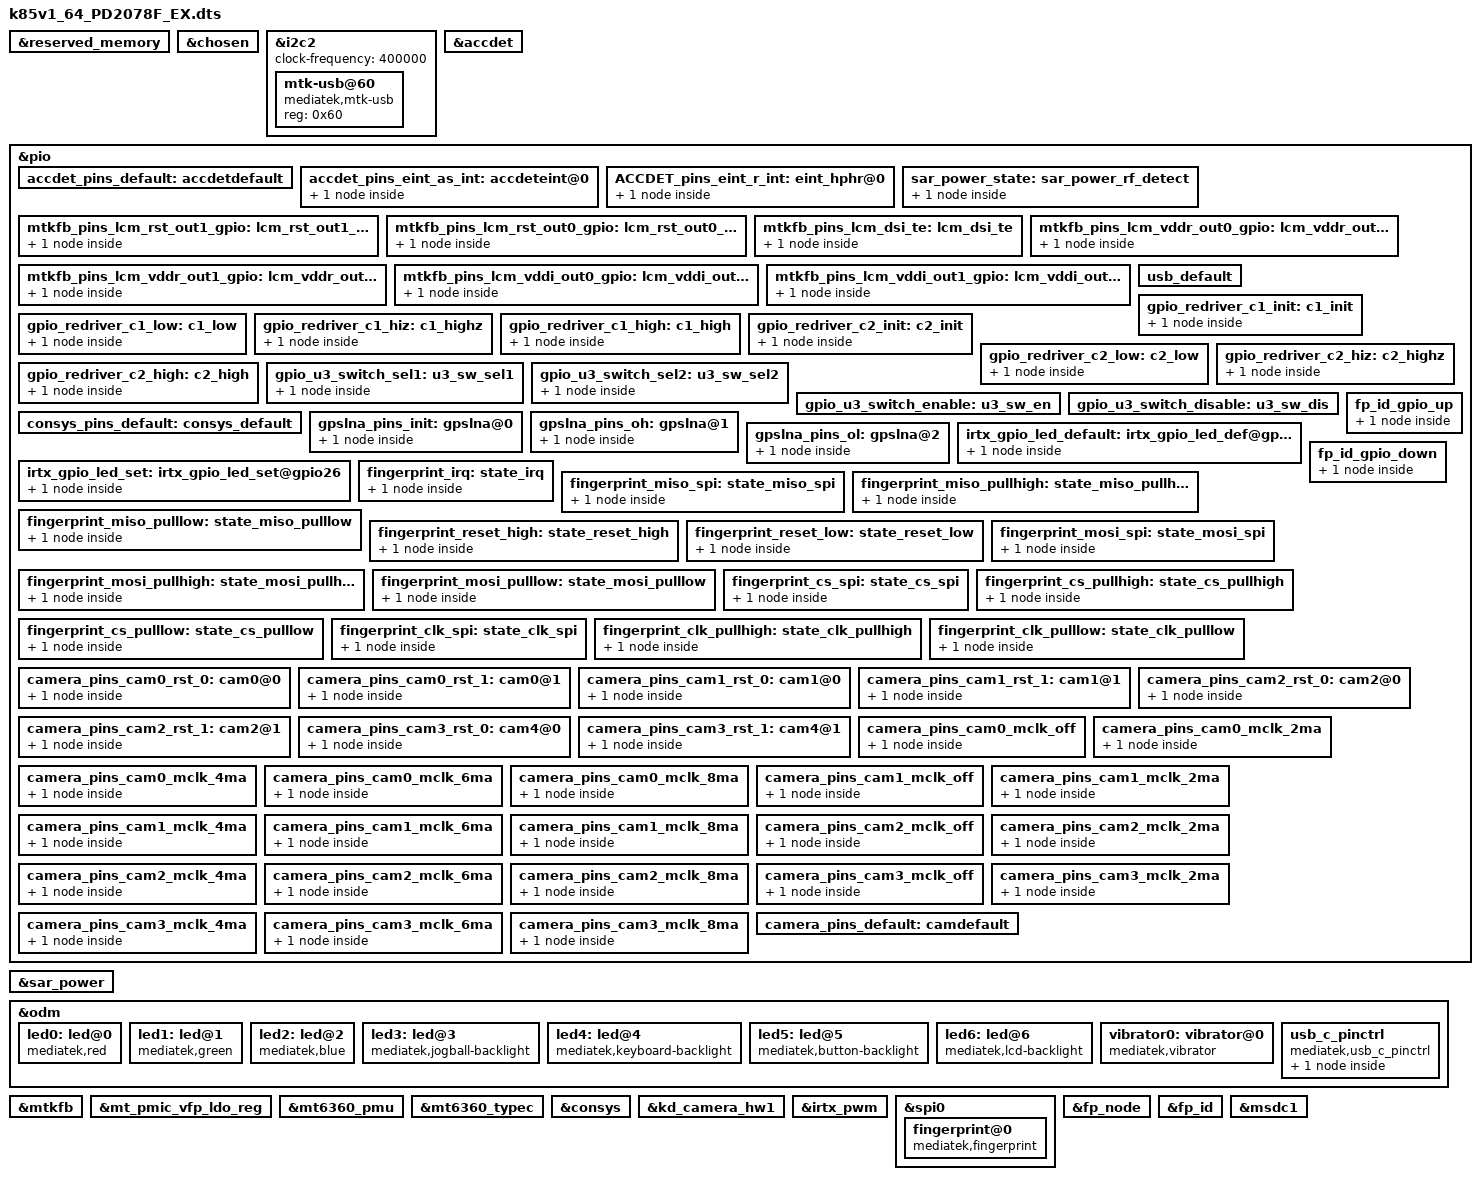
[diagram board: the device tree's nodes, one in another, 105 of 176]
/*
 * Copyright (C) 2015 MediaTek Inc.
 *
 * This program is free software: you can redistribute it and/or modify
 * it under the terms of the GNU General Public License version 2 as
 * published by the Free Software Foundation.
 *
 * This program is distributed in the hope that it will be useful,
 * but WITHOUT ANY WARRANTY; without even the implied warranty of
 * MERCHANTABILITY or FITNESS FOR A PARTICULAR PURPOSE. See the
 * GNU General Public License for more details.
 */
/dts-v1/;
/plugin/;
#include <dt-bindings/interrupt-controller/irq.h>
#include <dt-bindings/interrupt-controller/arm-gic.h>
#include <dt-bindings/pinctrl/mt6785-pinfunc.h>

&reserved_memory {
};

/* chosen */
&chosen {
	/* fpga may has no lk, we need to specify display info here */
	/* fb buffer is reserved using this dts by memory node above */

	atag,videolfb-fb_base_l = <0x7e605000>;
	atag,videolfb-fb_base_h = <0x0>;
	atag,videolfb-islcmfound = <1>;
	atag,videolfb-islcm_inited = <0>;
	atag,videolfb-fps= <6000>;
	atag,videolfb-vramSize= <0x017e8000>;
	atag,videolfb-lcmname=
		"nt35695_fhd_dsi_cmd_truly_rt5081_drv";
	atag,videolfb-project-name= "PD2078F_EX";
};


&i2c2 {
	clock-frequency = <400000>;

	mtk-usb@60 {
		compatible = "mediatek,mtk-usb";
		reg = <0x60>;
		status = "okay";
	};
};

/* accdet start */
&accdet {
	/* accdet micbias voltage: 0x09:2.85v 0x08:2.8v 0x07,
	 * 2.7v;0x05,2.5v;0x02,1.9v
	 */
	accdet-mic-vol = <7>;
	/* accdet pwm_width, pwm_thresh, fall_delay, rise_delay
	 * debounce0, debounce1, debounce3, debounce4
	 * eint pwm_width, eint pwm_thresh
	 * eint deb(debounce0, debounce1, debounce2, debounce3), inv_debounce
	 */
	headset-mode-setting = <0x500 0x500 1 0x1f0
				0x800 0x800 0x2000 0x44
				0x4 0x1
				0x5 0x3 0x3 0x5 0xe>;
	accdet-plugout-debounce = <16>;
	/*1:ACC mode, 2:low cost without in bias, 6:low cost with in bias*/
	accdet-mic-mode = <2>;
	/*0--MD_MAX--UP_MAX--DW_MAX*/
	headset-three-key-threshold = <0 90 210 430>;
	headset-three-key-threshold-CDD = <0 121 192 600>;
	/*0--MD_MAX--VOICE_MAX--UP_MAX--DW_MAX*/
	headset-four-key-threshold = <0 33 60 189 430>;

	/* select VTH to 2v and 500k, use internal resitance */
	eint_use_ext_res = <0>;
	pinctrl-names = "default", "state_eint_as_int","state_eint_r_as_int";
	pinctrl-0 = <&accdet_pins_default>;
	pinctrl-1 = <&accdet_pins_eint_as_int>;
	pinctrl-2 = <&ACCDET_pins_eint_r_int>;
	status = "okay";
};
&pio {
	accdet_pins_default: accdetdefault {
	};
	accdet_pins_eint_as_int: accdeteint@0 {
		pins_cmd_dat {
			pinmux = <PINMUX_GPIO9__FUNC_GPIO9>;
			slew-rate = <0>;
			bias-disable;
		};
	};
	ACCDET_pins_eint_r_int:eint_hphr@0{
			pins_cmd_dat {
				pinmux = <PINMUX_GPIO1__FUNC_GPIO1>;
				slew-rate = <0>;
				bias-disable;
			};
	};
};
/* accdet end */

/* ADD by vsensor team for SAR Power */
&pio {
	sar_power_state: sar_power_rf_detect {
		pins_cmd0_dat {
			pinmux = <PINMUX_GPIO6__FUNC_GPIO6>;
			slew-rate = <0>;
			bias-disable;
		};
	};
};

&sar_power {
	status="okay";
	pinctrl-names = "default";
	pinctrl-0 = <&sar_power_state>;
	sar-power-rf-detect,gpios= <&pio 6 0x0>;
};
/* ADD by vsensor team for SAR Power */

/* feature : $enable $dl_mem $ul_mem $ref_mem */
//&snd_audio_dsp {
//	compatible = "mediatek,snd_audio_dsp";
//	mtk_dsp_voip = <0x1f 0xffffffff 0xffffffff 0xffffffff 0x30000>;
//	mtk_dsp_primary = <0x5 0xffffffff 0xffffffff 0xffffffff 0x30000>;
//	mtk_dsp_offload = <0x0 0xffffffff 0xffffffff 0xffffffff 0x400000>;
//	mtk_dsp_deep = <0x5 0xffffffff 0xffffffff 0xffffffff 0x30000>;
//	mtk_dsp_playback = <0x1 0x4 0xffffffff 0x14 0x30000>;
//	mtk_dsp_music = <0x1 0xffffffff 0xffffffff 0xffffffff 0x0>;
//	mtk_dsp_capture1 = <0x1 0xffffffff 0xd 0x13 0x20000>;
//	mtk_dsp_a2dp = <0x0 0xffffffff 0xffffffff 0xffffffff 0x40000>;
//	mtk_dsp_dataprovider = <0x0 0xffffffff 0xf 0xffffffff 0x30000>;
//	mtk_dsp_call_final = <0x5 0x0 0x10 0x14 0x18000>;
//	mtk_dsp_fast = <0x5 0xffffffff 0xffffffff 0xffffffff 0x5000>;
//	mtk_dsp_ktv = <0x0 0x8 0x12 0xffffffff 0x10000>;
//	mtk_dsp_capture_raw = <0x0 0xffffffff 0xffffffff 0xffffffff 0x20000>;
//	mtk_dsp_ver = <0x0>;
//	swdsp_smartpa_process_enable = <0x5>;
//	mtk_dsp_mem_afe = <0x1 0x40000>; /* always enable */
//};

&odm {
	led0:led@0 {
		compatible = "mediatek,red";
		led_mode = <0>;
		data = <1>;
		pwm_config = <0 0 0 0 0>;
	};
	led1:led@1 {
		compatible = "mediatek,green";
		led_mode = <0>;
		data = <1>;
		pwm_config = <0 0 0 0 0>;
	};
	led2:led@2 {
		compatible = "mediatek,blue";
		led_mode = <0>;
		data = <1>;
		pwm_config = <0 0 0 0 0>;
	};
	led3:led@3 {
		compatible = "mediatek,jogball-backlight";
		led_mode = <0>;
		data = <1>;
		pwm_config = <0 0 0 0 0>;
	};
	led4:led@4 {
		compatible = "mediatek,keyboard-backlight";
		led_mode = <0>;
		data = <1>;
		pwm_config = <0 0 0 0 0>;
	};
	led5:led@5 {
		compatible = "mediatek,button-backlight";
		led_mode = <0>;
		data = <1>;
		pwm_config = <0 0 0 0 0>;
	};
	led6:led@6 {
		compatible = "mediatek,lcd-backlight";
		led_mode = <4>;
		data = <1>;
		pwm_config = <0 1 0 0 0>;
	};
	vibrator0:vibrator@0 {
		compatible = "mediatek,vibrator";
		vib_timer = <25>;
		vib_limit = <9>;
		vib_vol= <11>;
	};

	usb_c_pinctrl:usb_c_pinctrl {
		compatible = "mediatek,usb_c_pinctrl";
	};
};

/* DISPSYS GPIO standardization */
&pio {
	mtkfb_pins_lcm_rst_out1_gpio: lcm_rst_out1_gpio {
		pins_cmd_dat {
			pinmux = <PINMUX_GPIO44__FUNC_GPIO44>;
			slew-rate = <1>;
			output-high;
		};
	};

	mtkfb_pins_lcm_rst_out0_gpio: lcm_rst_out0_gpio {
		pins_cmd_dat {
			pinmux = <PINMUX_GPIO44__FUNC_GPIO44>;
			slew-rate = <1>;
			output-low;
		};
	};
	mtkfb_pins_lcm_dsi_te: lcm_dsi_te {
		pins_cmd_dat {
			pinmux = <PINMUX_GPIO43__FUNC_DSI_TE>;
		};
	};
		
	mtkfb_pins_lcm_vddr_out0_gpio: lcm_vddr_out0_gpio {
		pins_cmd_dat {
			pinmux = <PINMUX_GPIO87__FUNC_GPIO87>;
			slew-rate = <1>;
			output-low;
		};
	};

	mtkfb_pins_lcm_vddr_out1_gpio: lcm_vddr_out1_gpio {
		pins_cmd_dat {
			pinmux = <PINMUX_GPIO87__FUNC_GPIO87>;
			slew-rate = <1>;
			output-high;
		};
	};

	mtkfb_pins_lcm_vddi_out0_gpio: lcm_vddi_out0_gpio {
		pins_cmd_dat {
			pinmux = <PINMUX_GPIO154__FUNC_GPIO154>;
			slew-rate = <1>;
			output-low;
		};
	};

	mtkfb_pins_lcm_vddi_out1_gpio: lcm_vddi_out1_gpio {
		pins_cmd_dat {
			pinmux = <PINMUX_GPIO154__FUNC_GPIO154>;
			slew-rate = <1>;
			output-high;
		};
	};

};

&mtkfb {
	pinctrl-names = "lcm_rst_out1_gpio", "lcm_rst_out0_gpio",
		"mode_te_te",
		"lcm_vddr_out0_gpio","lcm_vddr_out1_gpio",
		"lcm_vddi_out0_gpio","lcm_vddi_out1_gpio";
	pinctrl-0 = <&mtkfb_pins_lcm_rst_out1_gpio>;
	pinctrl-1 = <&mtkfb_pins_lcm_rst_out0_gpio>;
	pinctrl-2 = <&mtkfb_pins_lcm_dsi_te>;
	pinctrl-3 = <&mtkfb_pins_lcm_vddr_out0_gpio>;
	pinctrl-4 = <&mtkfb_pins_lcm_vddr_out1_gpio>;
	pinctrl-5 = <&mtkfb_pins_lcm_vddi_out0_gpio>;
	pinctrl-6 = <&mtkfb_pins_lcm_vddi_out1_gpio>;
	status = "okay";
};

&mt_pmic_vfp_ldo_reg {
	regulator-name = "lcm_vci";
	regulator-min-microvolt = <3100000>;
	regulator-max-microvolt = <3100000>;
	status = "okay";
};

/* DISPSYS GPIO standardization end */
&mt6360_pmu {
	mt6360,intr_gpio_num = <16>; /* direct defined GPIO num */
	mt6360,intr_gpio = <&pio 16 0x0>;
};

&mt6360_typec {
	mt6360pd,intr_gpio_num = <7>; /* direct defined GPIO num */
	mt6360pd,intr_gpio = <&pio 7 0x0>;
	mt6360pd,pcb_gpio = <&pio 5 0x0>;
	mt6360pd,pcb_gpio_num = <5>;
	mt6360pd,pcb_gpio_polarity = <1>;
};

/* USB SWITCH GPIO start */
&pio {
	usb_default: usb_default {
	};

	gpio_redriver_c1_init: c1_init {
		pins_cmd_dat {
			pinmux = <PINMUX_GPIO31__FUNC_GPIO31>;
			slew-rate = <1>;
			output-low;
		};
	};

	gpio_redriver_c1_low: c1_low {
		pins_cmd_dat {
			pinmux = <PINMUX_GPIO31__FUNC_GPIO31>;
			slew-rate = <1>;
			output-low;
		};
	};

	gpio_redriver_c1_hiz: c1_highz {
		pins_cmd_dat {
			pinmux = <PINMUX_GPIO31__FUNC_GPIO31>;
			slew-rate= <0>;
			bias-disable;
		};
	};

	gpio_redriver_c1_high: c1_high {
		pins_cmd_dat {
			pinmux = <PINMUX_GPIO31__FUNC_GPIO31>;
			slew-rate = <1>;
			output-high;
		};
	};

	gpio_redriver_c2_init: c2_init {
		pins_cmd_dat {
			pinmux = <PINMUX_GPIO30__FUNC_GPIO30>;
			slew-rate = <1>;
			output-low;
		};
	};

	gpio_redriver_c2_low: c2_low {
		pins_cmd_dat {
			pinmux = <PINMUX_GPIO30__FUNC_GPIO30>;
			slew-rate = <1>;
			output-low;
		};
	};

	gpio_redriver_c2_hiz: c2_highz {
		pins_cmd_dat {
			pinmux = <PINMUX_GPIO30__FUNC_GPIO30>;
			slew-rate= <0>;
			bias-disable;
		};
	};

	gpio_redriver_c2_high: c2_high {
		pins_cmd_dat {
			pinmux = <PINMUX_GPIO30__FUNC_GPIO30>;
			slew-rate = <1>;
			output-high;
		};
	};

	gpio_u3_switch_sel1: u3_sw_sel1 {
		pins_cmd_dat {
			pinmux = <PINMUX_GPIO32__FUNC_GPIO32>;
			slew-rate = <1>;
			output-low;
		};
	};

	gpio_u3_switch_sel2: u3_sw_sel2 {
		pins_cmd_dat {
			pinmux = <PINMUX_GPIO32__FUNC_GPIO32>;
			slew-rate = <1>;
			output-high;
		};
	};

	gpio_u3_switch_enable: u3_sw_en {
	};

	gpio_u3_switch_disable: u3_sw_dis {
	};
};

&usb_c_pinctrl {
	pinctrl-names = "usb_default",
		"redrv_c1_init",
		"redrv_c1_low",
		"redrv_c1_hiz",
		"redrv_c1_high",
		"redrv_c2_init",
		"redrv_c2_low",
		"redrv_c2_hiz",
		"redrv_c2_high",
		"switch_sel1",
		"switch_sel2",
		"switch_enable",
		"switch_disable";

	pinctrl-0 = <&usb_default>;
	pinctrl-1 = <&gpio_redriver_c1_init>;
	pinctrl-2 = <&gpio_redriver_c1_low>;
	pinctrl-3 = <&gpio_redriver_c1_hiz>;
	pinctrl-4 = <&gpio_redriver_c1_high>;
	pinctrl-5 = <&gpio_redriver_c2_init>;
	pinctrl-6 = <&gpio_redriver_c2_low>;
	pinctrl-7 = <&gpio_redriver_c2_hiz>;
	pinctrl-8 = <&gpio_redriver_c2_high>;
	pinctrl-9 = <&gpio_u3_switch_sel1>;
	pinctrl-10 = <&gpio_u3_switch_sel2>;
	pinctrl-11 = <&gpio_u3_switch_enable>;
	pinctrl-12 = <&gpio_u3_switch_disable>;
	status = "okay";

	usb_switch-data {
		en_pin_num = <0>;
		en_pin_val = <0>;
		sel_pin_num = <32>;
		sel_pin_val = <1>;
		c1_pin_num = <31>;
		c1_pin_val = <2>;
		c2_pin_num = <30>;
		c2_pin_val = <1>;
	};
};
/* USB SWITCH GPIO end */

/* CONSYS GPIO standardization */
&pio {
	consys_pins_default: consys_default {
	};
	gpslna_pins_init: gpslna@0 {
		pins_cmd_dat {
			pinmux = <PINMUX_GPIO155__FUNC_GPIO155>;
			slew-rate = <0>;
			bias-disable;
			output-low;
		};
	};
	gpslna_pins_oh: gpslna@1 {
		pins_cmd_dat {
			pinmux = <PINMUX_GPIO155__FUNC_GPIO155>;
			slew-rate = <1>;
			output-high;
		};
	};
	gpslna_pins_ol: gpslna@2 {
		pins_cmd_dat {
			pinmux = <PINMUX_GPIO155__FUNC_GPIO155>;
			slew-rate = <1>;
			output-low;
		};
	};
};
&consys {
	pinctrl-names = "default", "gps_lna_state_init",
		"gps_lna_state_oh", "gps_lna_state_ol";
	pinctrl-0 = <&consys_pins_default>;
	pinctrl-1 = <&gpslna_pins_init>;
	pinctrl-2 = <&gpslna_pins_oh>;
	pinctrl-3 = <&gpslna_pins_ol>;
	status = "okay";
};
/* CONSYS end */

/* CAMERA specify sensor */
&kd_camera_hw1 {
	cam2_enable_sensor = "imx350_mipi_raw imx386_mipi_mono";
};
/* CAMERA specify sensor end */

/* IRTX GPIO Start */
&irtx_pwm {
	pinctrl-names = "irtx_gpio_led_default", "irtx_gpio_led_set";
	pinctrl-0 = <&irtx_gpio_led_default>;
	pinctrl-1 = <&irtx_gpio_led_set>;
	status = "okay";
};
&pio {
	/* IRTX GPIO Settings -Start */
	/* default: GPIO0, output, high */
	irtx_gpio_led_default:irtx_gpio_led_def@gpio26 {
		pins_cmd_dat {
			pinmux = <PINMUX_GPIO26__FUNC_GPIO26>;
			slew-rate = <1>;
			bias-disable;
			output-low;
			input-schmitt-enable = <0>;
		};
	};

	irtx_gpio_led_set:irtx_gpio_led_set@gpio26 {
		pins_cmd_dat {
			pinmux = <PINMUX_GPIO26__FUNC_PWM_0>;
			slew-rate = <1>;
			output-high;
		};
	};
}; /* IRTX GPIO Settings -End */

/* FINGERPRINT start */
&spi0 {
	#address-cells = <1>;
	#size-cells = <0>;
	fingerprint@0 {
		compatible = "mediatek,fingerprint";
		reg = <0>;
		spi-max-frequency = <8000000>;
		netlink-event = <30>;
		// vfp-supply = <&mt_pmic_vfp_ldo_reg>;
		power-type = <1>;
		status = "okay";
	};
};

&fp_node {
	interrupt-parent = <&pio>;
	interrupts = <3 IRQ_TYPE_EDGE_RISING 3 0>;
	// fp,vdd_use_pmic;
	// vfp-supply = <&mt_pmic_vfp_ldo_reg>;
	fp,vdd_use_gpio;
	fp,gpio_vdd_en = <&pio 82 0>;
	fp,vddio_use_gpio;
	fp,gpio_vddio_en = <&pio 81 0>;
	fpc,enable-wakeup;
	status = "okay";
	pinctrl-names = "fingerprint_irq", "miso_spi", "miso_pullhigh", "miso_pulllow", "reset_high", "reset_low","mosi_spi","mosi_pullhigh","mosi_pulllow","cs_spi","cs_pullhigh","cs_pulllow","clk_spi","clk_pullhigh","clk_pulllow";
	pinctrl-0 = <&fingerprint_irq>;
	pinctrl-1 = <&fingerprint_miso_spi>;
	pinctrl-2 = <&fingerprint_miso_pullhigh>;
	pinctrl-3 = <&fingerprint_miso_pulllow>;
	pinctrl-4 = <&fingerprint_reset_high>;
	pinctrl-5 = <&fingerprint_reset_low>;
	pinctrl-6 = <&fingerprint_mosi_spi>;
	pinctrl-7 = <&fingerprint_mosi_pullhigh>;
	pinctrl-8 = <&fingerprint_mosi_pulllow>;
	pinctrl-9 = <&fingerprint_cs_spi>;
	pinctrl-10 = <&fingerprint_cs_pullhigh>;
	pinctrl-11 = <&fingerprint_cs_pulllow>;
	pinctrl-12 = <&fingerprint_clk_spi>;
	pinctrl-13 = <&fingerprint_clk_pullhigh>;
	pinctrl-14 = <&fingerprint_clk_pulllow>;
};

&pio {
	fingerprint_irq: state_irq {
		pins_cmd_dat {
			pinmux = <PINMUX_GPIO3__FUNC_GPIO3>;
			slew-rate = <0>;
			bias-disable;
		};
	};

	fingerprint_miso_spi: state_miso_spi {
		pins_cmd_dat {
			pinmux = <PINMUX_GPIO17__FUNC_SPI0_A_MI>;
			drive-strength = <3>;
		};
	};

	fingerprint_miso_pullhigh: state_miso_pullhigh {
		pins_cmd_dat {
			pinmux = <PINMUX_GPIO17__FUNC_GPIO17>;
			slew-rate = <1>;
			output-high;
		};
	};

	fingerprint_miso_pulllow: state_miso_pulllow {
		pins_cmd_dat {
			pinmux = <PINMUX_GPIO17__FUNC_GPIO17>;
			slew-rate = <1>;
			output-low;
		};
	};

	fingerprint_reset_high: state_reset_high {
		pins_cmd_dat {
			pinmux = <PINMUX_GPIO197__FUNC_GPIO197>;
			slew-rate = <1>;
			output-high;
		};
	};

	fingerprint_reset_low: state_reset_low {
		pins_cmd_dat {
			pinmux = <PINMUX_GPIO197__FUNC_GPIO197>;
			slew-rate = <1>;
			output-low;
		};
	};

	fingerprint_mosi_spi: state_mosi_spi {
		pins_cmd_dat {
			pinmux = <PINMUX_GPIO18__FUNC_SPI0_A_MO>;
			drive-strength = <4>;
		};
	};
	fingerprint_mosi_pullhigh: state_mosi_pullhigh {
		pins_cmd_dat {
			pinmux = <PINMUX_GPIO18__FUNC_GPIO18>;
			slew-rate = <1>;
			output-high;
		};
	};

	fingerprint_mosi_pulllow: state_mosi_pulllow {
		pins_cmd_dat {
			pinmux = <PINMUX_GPIO18__FUNC_GPIO18>;
			slew-rate = <1>;
			output-low;
		};
	};
	fingerprint_cs_spi: state_cs_spi {
		pins_cmd_dat {
			pinmux = <PINMUX_GPIO19__FUNC_SPI0_A_CSB>;
			drive-strength = <3>;
		};
	};

	fingerprint_cs_pullhigh: state_cs_pullhigh {
		pins_cmd_dat {
			pinmux = <PINMUX_GPIO19__FUNC_GPIO19>;
			slew-rate = <1>;
			output-high;
		};
	};

	fingerprint_cs_pulllow: state_cs_pulllow {
		pins_cmd_dat {
			pinmux = <PINMUX_GPIO19__FUNC_GPIO19>;
			slew-rate = <1>;
			output-low;
		};
	};

	fingerprint_clk_spi: state_clk_spi {
		pins_cmd_dat {
			pinmux = <PINMUX_GPIO20__FUNC_SPI0_A_CLK>;
			drive-strength = <4>;
		};
	};
	fingerprint_clk_pullhigh: state_clk_pullhigh {
		pins_cmd_dat {
			pinmux = <PINMUX_GPIO20__FUNC_GPIO20>;
			slew-rate = <1>;
			output-high;
		};
	};

	fingerprint_clk_pulllow: state_clk_pulllow {
		pins_cmd_dat {
			pinmux = <PINMUX_GPIO20__FUNC_GPIO20>;
			slew-rate = <1>;
			output-low;
		};
	};
};
&pio {
	fp_id_gpio_up: fp_id_gpio_up {
		pins_cmd_dat {
			pinmux = <PINMUX_GPIO8__FUNC_GPIO8>;
			slew-rate = <0>;
			bias-pull-up;
			input-enable;
		};
	};
	fp_id_gpio_down: fp_id_gpio_down {
		pins_cmd_dat {
			pinmux = <PINMUX_GPIO8__FUNC_GPIO8>;
			slew-rate = <0>;
			bias-pull-down;
			input-enable;
		};
	};
};

&fp_id {
	status="okay";
	vivo,project-name = "PD2078F_EX";
	//vcc_silead-supply = <&mt_pmic_vfp_ldo_reg>;
	fp_id,gpios= <&pio 12 0>;
	pinctrl-names = "fp_gpio_pull_up",
					"fp_gpio_pull_down";
	pinctrl-0 = <&fp_id_gpio_up>;
	pinctrl-1 = <&fp_id_gpio_down>;
};
/* FINGERPRINT end */

/* CAMERA GPIO standardization */
&pio {
	camera_pins_cam0_rst_0: cam0@0 {
		pins_cmd_dat {
			pinmux = <PINMUX_GPIO119__FUNC_GPIO119>;
			slew-rate = <1>;
			output-low;
		};
	};
	camera_pins_cam0_rst_1: cam0@1 {
		pins_cmd_dat {
			pinmux = <PINMUX_GPIO119__FUNC_GPIO119>;
			slew-rate = <1>;
			output-high;
		};
	};
	camera_pins_cam1_rst_0: cam1@0 {
		pins_cmd_dat {
			pinmux = <PINMUX_GPIO124__FUNC_GPIO124>;
			slew-rate = <1>;
			output-low;
		};
	};
	camera_pins_cam1_rst_1: cam1@1 {
		pins_cmd_dat {
			pinmux = <PINMUX_GPIO124__FUNC_GPIO124>;
			slew-rate = <1>;
			output-high;
		};
	};
	camera_pins_cam2_rst_0: cam2@0 {
		pins_cmd_dat {
			pinmux = <PINMUX_GPIO118__FUNC_GPIO118>;
			slew-rate = <1>;
			output-low;
		};
	};
	camera_pins_cam2_rst_1: cam2@1 {
		pins_cmd_dat {
			pinmux = <PINMUX_GPIO118__FUNC_GPIO118>;
			slew-rate = <1>;
			output-high;
		};
	};
	camera_pins_cam3_rst_0: cam4@0 {
		pins_cmd_dat {
			pinmux = <PINMUX_GPIO125__FUNC_GPIO125>;
			slew-rate = <1>;
			output-low;
		};
	};
	camera_pins_cam3_rst_1: cam4@1 {
		pins_cmd_dat {
			pinmux = <PINMUX_GPIO125__FUNC_GPIO125>;
			slew-rate = <1>;
			output-high;
		};
	};

	camera_pins_cam0_mclk_off: camera_pins_cam0_mclk_off {
		pins_cmd_dat {
			pinmux = <PINMUX_GPIO117__FUNC_GPIO117>;
			drive-strength = <1>;
		};
	};
	camera_pins_cam0_mclk_2ma: camera_pins_cam0_mclk_2ma {
		pins_cmd_dat {
			pinmux = <PINMUX_GPIO117__FUNC_CMMCLK1>;
			drive-strength = <0>;
		};
	};
	camera_pins_cam0_mclk_4ma: camera_pins_cam0_mclk_4ma {
		pins_cmd_dat {
			pinmux = <PINMUX_GPIO117__FUNC_CMMCLK1>;
			drive-strength = <1>;
		};
	};
	camera_pins_cam0_mclk_6ma: camera_pins_cam0_mclk_6ma {
		pins_cmd_dat {
			pinmux = <PINMUX_GPIO117__FUNC_CMMCLK1>;
			drive-strength = <2>;
		};
	};
	camera_pins_cam0_mclk_8ma: camera_pins_cam0_mclk_8ma {
		pins_cmd_dat {
			pinmux = <PINMUX_GPIO117__FUNC_CMMCLK1>;
			drive-strength = <3>;
		};
	};

	camera_pins_cam1_mclk_off: camera_pins_cam1_mclk_off {
		pins_cmd_dat {
			pinmux = <PINMUX_GPIO120__FUNC_GPIO120>;
			drive-strength = <1>;
		};
	};
	camera_pins_cam1_mclk_2ma: camera_pins_cam1_mclk_2ma {
		pins_cmd_dat {
			pinmux = <PINMUX_GPIO120__FUNC_CMMCLK2>;
			drive-strength = <0>;
		};
	};
	camera_pins_cam1_mclk_4ma: camera_pins_cam1_mclk_4ma {
		pins_cmd_dat {
			pinmux = <PINMUX_GPIO120__FUNC_CMMCLK2>;
			drive-strength = <1>;
		};
	};
	camera_pins_cam1_mclk_6ma: camera_pins_cam1_mclk_6ma {
		pins_cmd_dat {
			pinmux = <PINMUX_GPIO120__FUNC_CMMCLK2>;
			drive-strength = <2>;
		};
	};
	camera_pins_cam1_mclk_8ma: camera_pins_cam1_mclk_8ma {
		pins_cmd_dat {
			pinmux = <PINMUX_GPIO120__FUNC_CMMCLK2>;
			drive-strength = <3>;
		};
	};


	camera_pins_cam2_mclk_off: camera_pins_cam2_mclk_off {
		pins_cmd_dat {
			pinmux = <PINMUX_GPIO116__FUNC_GPIO116>;
			drive-strength = <1>;
		};
	};
	camera_pins_cam2_mclk_2ma: camera_pins_cam2_mclk_2ma {
		pins_cmd_dat {
			pinmux = <PINMUX_GPIO116__FUNC_CMMCLK0>;
			drive-strength = <0>;
		};
	};
	camera_pins_cam2_mclk_4ma: camera_pins_cam2_mclk_4ma {
		pins_cmd_dat {
			pinmux = <PINMUX_GPIO116__FUNC_CMMCLK0>;
			drive-strength = <1>;
		};
	};
	camera_pins_cam2_mclk_6ma: camera_pins_cam2_mclk_6ma {
		pins_cmd_dat {
			pinmux = <PINMUX_GPIO116__FUNC_CMMCLK0>;
			drive-strength = <2>;
		};
	};
	camera_pins_cam2_mclk_8ma: camera_pins_cam2_mclk_8ma {
		pins_cmd_dat {
			pinmux = <PINMUX_GPIO116__FUNC_CMMCLK0>;
			drive-strength = <3>;
		};
	};

	camera_pins_cam3_mclk_off: camera_pins_cam3_mclk_off {
		pins_cmd_dat {
			pinmux = <PINMUX_GPIO121__FUNC_GPIO121>;
			drive-strength = <1>;
		};
	};
	camera_pins_cam3_mclk_2ma: camera_pins_cam3_mclk_2ma {
		pins_cmd_dat {
			pinmux = <PINMUX_GPIO121__FUNC_CMMCLK3>;
			drive-strength = <0>;
		};
	};
	camera_pins_cam3_mclk_4ma: camera_pins_cam3_mclk_4ma {
		pins_cmd_dat {
			pinmux = <PINMUX_GPIO121__FUNC_CMMCLK3>;
			drive-strength = <1>;
		};
	};
	camera_pins_cam3_mclk_6ma: camera_pins_cam3_mclk_6ma {
		pins_cmd_dat {
			pinmux = <PINMUX_GPIO121__FUNC_CMMCLK3>;
			drive-strength = <2>;
		};
	};
	camera_pins_cam3_mclk_8ma: camera_pins_cam3_mclk_8ma {
		pins_cmd_dat {
			pinmux = <PINMUX_GPIO121__FUNC_CMMCLK3>;
			drive-strength = <3>;
		};
	};

	camera_pins_default: camdefault {
	};
};
&kd_camera_hw1 {
	pinctrl-names = "default",
			"cam0_rst0", "cam0_rst1",
			"cam1_rst0", "cam1_rst1",
			"cam2_rst0", "cam2_rst1",
			"cam3_rst0", "cam3_rst1",
			"cam0_mclk_off",
			"cam0_mclk_2mA", "cam0_mclk_4mA",
			"cam0_mclk_6mA", "cam0_mclk_8mA",
			"cam1_mclk_off",
			"cam1_mclk_2mA", "cam1_mclk_4mA",
			"cam1_mclk_6mA", "cam1_mclk_8mA",
			"cam2_mclk_off",
			"cam2_mclk_2mA", "cam2_mclk_4mA",
			"cam2_mclk_6mA", "cam2_mclk_8mA",
			"cam3_mclk_off",
			"cam3_mclk_2mA", "cam3_mclk_4mA",
			"cam3_mclk_6mA", "cam3_mclk_8mA";
	pinctrl-0 = <&camera_pins_default>;
	pinctrl-1 = <&camera_pins_cam0_rst_0>;
	pinctrl-2 = <&camera_pins_cam0_rst_1>;
	pinctrl-3 = <&camera_pins_cam1_rst_0>;
	pinctrl-4 = <&camera_pins_cam1_rst_1>;
	pinctrl-5 = <&camera_pins_cam2_rst_0>;
	pinctrl-6 = <&camera_pins_cam2_rst_1>;
	pinctrl-7 = <&camera_pins_cam3_rst_0>;
	pinctrl-8 = <&camera_pins_cam3_rst_1>;
	pinctrl-9 = <&camera_pins_cam0_mclk_off>;
	pinctrl-10 = <&camera_pins_cam0_mclk_2ma>;
	pinctrl-11 = <&camera_pins_cam0_mclk_4ma>;
	pinctrl-12 = <&camera_pins_cam0_mclk_6ma>;
	pinctrl-13 = <&camera_pins_cam0_mclk_8ma>;
	pinctrl-14 = <&camera_pins_cam1_mclk_off>;
	pinctrl-15 = <&camera_pins_cam1_mclk_2ma>;
	pinctrl-16 = <&camera_pins_cam1_mclk_4ma>;
	pinctrl-17 = <&camera_pins_cam1_mclk_6ma>;
	pinctrl-18 = <&camera_pins_cam1_mclk_8ma>;
	pinctrl-19 = <&camera_pins_cam2_mclk_off>;
	pinctrl-20 = <&camera_pins_cam2_mclk_2ma>;
	pinctrl-21 = <&camera_pins_cam2_mclk_4ma>;
	pinctrl-22 = <&camera_pins_cam2_mclk_6ma>;
	pinctrl-23 = <&camera_pins_cam2_mclk_8ma>;
	pinctrl-24 = <&camera_pins_cam3_mclk_off>;
	pinctrl-25 = <&camera_pins_cam3_mclk_2ma>;
	pinctrl-26 = <&camera_pins_cam3_mclk_4ma>;
	pinctrl-27 = <&camera_pins_cam3_mclk_6ma>;
	pinctrl-28 = <&camera_pins_cam3_mclk_8ma>;
	
	status = "okay";
};
/* CAMERA GPIO end */

&msdc1 {
	fast_power_off;
	PD2078F_EX;
	vmc_vol_1800;
};

#include "mediatek/cust_vivo_PD2078F_EX.dtsi"
/*#include "mediatek/cust_mt6785_camera.dtsi"*/
#include "mediatek/vivo_tp_setting/mt6785-vivo-tp-PD2078F_EX.dtsi"
/*End of this file, DO NOT ADD ANYTHING HERE*/
